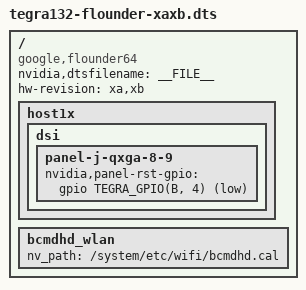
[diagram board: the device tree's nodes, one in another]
/dts-v1/;

#include "tegra132-flounder-generic.dtsi"

/ {
	compatible = "google,flounder64", "nvidia,tegra132", "nvidia,tn8";
	nvidia,dtsfilename = __FILE__;
	hw-revision = "xa,xb";

        host1x {
		dsi {
			panel-j-qxga-8-9 {
				nvidia,panel-rst-gpio = <&gpio TEGRA_GPIO(B, 4) GPIO_ACTIVE_LOW>;
			};
		};
	};

	bcmdhd_wlan {
		nv_path = "/system/etc/wifi/bcmdhd.cal";
	};
};

